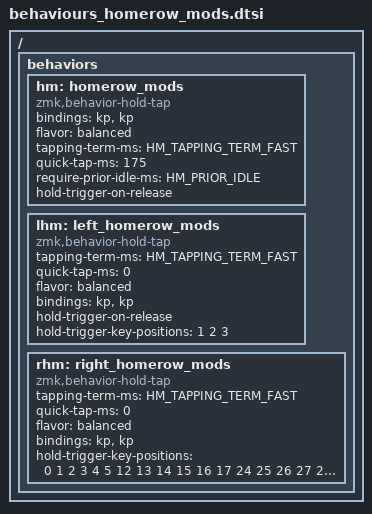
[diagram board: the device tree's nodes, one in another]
// Make sure settings.dtsi is included before this file

#define HM_TAPPING_TERM 300
#define HM_TAPPING_TERM_FAST 5000
#define HM_PRIOR_IDLE 150

/ {

    behaviors {
        /*
         * Non-Positional Homerow Mods
         * Used for &mm_grescm_gui behavior on left hand.
         *
         * Usage: &hm LSHFT T
         * Tap: T
         * Tap-Tap-Hold: Repeat T
         * Hold: LSHIFT
         */
        hm: homerow_mods {
            compatible = "zmk,behavior-hold-tap";
            #binding-cells = <2>;
            bindings = <&kp>, <&kp>;

            flavor = "balanced";
            tapping-term-ms = <HM_TAPPING_TERM_FAST>;
            quick-tap-ms = <175>;
            require-prior-idle-ms = <HM_PRIOR_IDLE>;

            hold-trigger-on-release;

            /*hold-trigger-key-positions 1;
            */
        };

        lhm: left_homerow_mods {
            compatible = "zmk,behavior-hold-tap";
            #binding-cells = <2>;
            tapping-term-ms = <HM_TAPPING_TERM_FAST>;
            quick-tap-ms = <0>;
            flavor = "balanced";
            bindings = <&kp>, <&kp>;
            hold-trigger-on-release;
            hold-trigger-key-positions = <1 2 3>;
        }; 

        rhm: right_homerow_mods {
            compatible = "zmk,behavior-hold-tap";
            #binding-cells = <2>;
            tapping-term-ms = <HM_TAPPING_TERM_FAST>;
            quick-tap-ms = <0>;
            flavor = "balanced";
            bindings = <&kp>, <&kp>;
            hold-trigger-key-positions = <0 1 2 3 4  5  12 13 14 15 16 17 24 25 26 27 28 29 36 37 38 39 40 41>;
        };

    };
};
